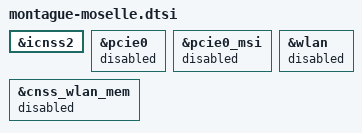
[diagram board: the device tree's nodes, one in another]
#include "montague-hsp.dtsi"

&icnss2 {
	status = "ok";
};

&pcie0 {
	status = "disabled";
};

&pcie0_msi {
	status = "disabled";
};

&wlan {
	status = "disabled";
};

&cnss_wlan_mem {
	status = "disabled";
};
